AUTOSAR XML (schema 314)
package /ComponentType
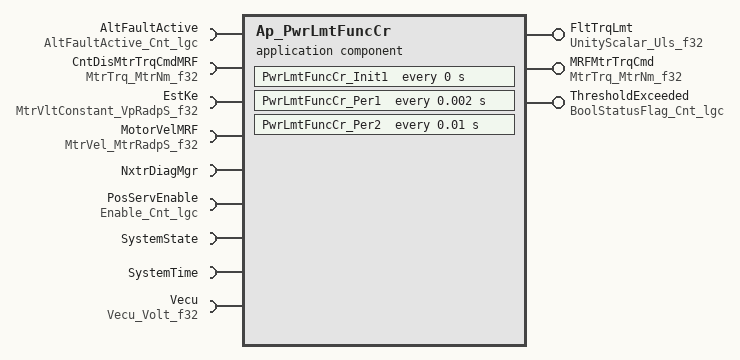
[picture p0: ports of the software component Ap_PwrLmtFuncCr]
  application software component type Ap_PwrLmtFuncCr
    provide port FltTrqLmt: unqueued-sender-com-spec{data-element=Uls_f32, can-invalidate=false, init-value=D_ZERO_ULS_F32}, provided-interface=UnityScalar_Uls_f32
    provide port MRFMtrTrqCmd: unqueued-sender-com-spec{data-element=MtrNm_f32, can-invalidate=false, init-value=D_ZERO_ULS_F32}, provided-interface=MtrTrq_MtrNm_f32
    provide port ThresholdExceeded: unqueued-sender-com-spec{data-element=Cnt_lgc, can-invalidate=false, init-value=D_FALSE_CNT_LGC}, provided-interface=BoolStatusFlag_Cnt_lgc
    9 x require port:
      AltFaultActive: unqueued-receiver-com-spec{data-element=Cnt_lgc, init-value=D_FALSE_CNT_LGC}, required-interface=AltFaultActive_Cnt_lgc
      CntDisMtrTrqCmdMRF: unqueued-receiver-com-spec{data-element=MtrNm_f32, init-value=D_ZERO_ULS_F32}, required-interface=MtrTrq_MtrNm_f32
      EstKe: unqueued-receiver-com-spec{data-element=VpRadpS_f32, init-value=D_ZERO_ULS_F32}, required-interface=MtrVltConstant_VpRadpS_f32
      MotorVelMRF: unqueued-receiver-com-spec{data-element=MtrRadpS_f32, init-value=D_ZERO_ULS_F32}, required-interface=MtrVel_MtrRadpS_f32
      NxtrDiagMgr: required-com-specs=[GetNTCActive, GetNTCFailed, GetNTCStatus, SetNTCStatus], required-interface=NxtrDiagMgr
      PosServEnable: unqueued-receiver-com-spec{data-element=Cnt_lgc, init-value=D_FALSE_CNT_LGC}, required-interface=Enable_Cnt_lgc
      SystemState: required-interface=SystemState
      SystemTime: required-interface=SystemTime
        required-com-specs:
          DtrmnElapsedTime_mS_u16
          DtrmnElapsedTime_mS_u32
          DtrmnElapsedTime_uS_u16
          DtrmnElapsedTime_uS_u32
          GetSystemTime_mS_u32
          GetSystemTime_uS_u32
      Vecu: unqueued-receiver-com-spec{data-element=Volt_f32, init-value=D_VECUMIN_VOLTS_F32}, required-interface=Vecu_Volt_f32
  internal behavior Ap_PwrLmtFuncCr_InternalBehavior: component=Ap_PwrLmtFuncCr
    timing event PwrLmtFuncCr_Init1_InitEvent: start-on-event=PwrLmtFuncCr_Init1, period=0
    timing event TMT_PwrLmtFuncCr_Per1: mode-dependency=dependent-on-mode=[SystemState.Mode.DISABLE, SystemState.Mode.OFF, SystemState.Mode.WARMINIT], start-on-event=PwrLmtFuncCr_Per1, period=0.002
    timing event TMT_PwrLmtFuncCr_Per2: mode-dependency=dependent-on-mode=[SystemState.Mode.DISABLE, SystemState.Mode.OFF, SystemState.Mode.WARMINIT], start-on-event=PwrLmtFuncCr_Per2, period=0.01
    port-api-options:
      enable-take-address=false, indirect-api=false, port=AltFaultActive
      enable-take-address=false, indirect-api=false, port=CntDisMtrTrqCmdMRF
      enable-take-address=false, indirect-api=false, port=EstKe
      enable-take-address=false, indirect-api=false, port=FltTrqLmt
      enable-take-address=false, indirect-api=false, port=MotorVelMRF
      enable-take-address=false, indirect-api=false, port=MRFMtrTrqCmd
      enable-take-address=false, indirect-api=false, port=NxtrDiagMgr
      enable-take-address=false, indirect-api=false, port=PosServEnable
      enable-take-address=false, indirect-api=false, port=SystemState
      enable-take-address=false, indirect-api=false, port=SystemTime
      enable-take-address=false, indirect-api=false, port=ThresholdExceeded
      enable-take-address=false, indirect-api=false, port=Vecu
    runnable PwrLmtFuncCr_Init1
      sync call SC_SystemTime_GetSystemTime_mS_u32: operation=SystemTime.GetSystemTime_mS_u32, timeout=0
    runnable PwrLmtFuncCr_Per1
      6 x data read access:
        READ_AltFaultActive_Cnt_lgc: data-element=AltFaultActive.Cnt_lgc
        READ_CntDisMtrTrqCmdMRF_MtrNm_f32: data-element=CntDisMtrTrqCmdMRF.MtrNm_f32
        READ_EstKe_VpRadpS_f32: data-element=EstKe.VpRadpS_f32
        READ_MotorVelMRF_MtrRadpS_f32: data-element=MotorVelMRF.MtrRadpS_f32
        READ_PosServEnable_Cnt_lgc: data-element=PosServEnable.Cnt_lgc
        READ_Vecu_Volt_f32: data-element=Vecu.Volt_f32
      data write access WRITE_MRFMtrTrqCmd_MtrNm_f32: data-element=MRFMtrTrqCmd.MtrNm_f32
    runnable PwrLmtFuncCr_Per2
      data read access READ_CntDisMtrTrqCmdMRF_MtrNm_f32: data-element=CntDisMtrTrqCmdMRF.MtrNm_f32
      data read access READ_Vecu_Volt_f32: data-element=Vecu.Volt_f32
      data write access WRITE_FltTrqLmt_Uls_f32: data-element=FltTrqLmt.Uls_f32
      data write access WRITE_ThresholdExceeded_Cnt_lgc: data-element=ThresholdExceeded.Cnt_lgc
      4 x sync call, all with timeout=0:
        SC_NxtrDiagMgr_GetNTCStatus: operation=NxtrDiagMgr.GetNTCStatus
        SC_NxtrDiagMgr_SetNTCStatus: operation=NxtrDiagMgr.SetNTCStatus
        SC_SystemTime_DtrmnElapsedTime_mS_u16: operation=SystemTime.DtrmnElapsedTime_mS_u16
        SC_SystemTime_GetSystemTime_mS_u32: operation=SystemTime.GetSystemTime_mS_u32
  swc implementation Ap_PwrLmtFuncCr_Implementation: behavior=Ap_PwrLmtFuncCr_InternalBehavior
    code-descriptors:
      code Code: type=SRC
